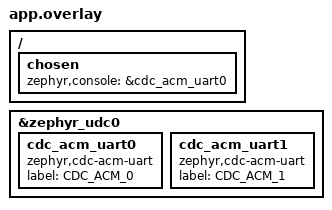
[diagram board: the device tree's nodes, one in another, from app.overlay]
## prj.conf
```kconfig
#
# Copyright (c) Ericsson AB 2020, all rights reserved
#

#General
CONFIG_REBOOT=y
CONFIG_HEAP_MEM_POOL_SIZE=16384
CONFIG_GPIO=y
CONFIG_POLL=y
CONFIG_BOOTLOADER_MCUBOOT=y

 # USB
CONFIG_USB_DEVICE_STACK=y
CONFIG_USB_DEVICE_MANUFACTURER="Ericcson AB"
CONFIG_USB_DEVICE_PRODUCT="Ardesco UART"
CONFIG_USB_DEVICE_VID=0x1915
CONFIG_USB_DEVICE_PID=0x520F
CONFIG_USB_DEVICE_SN="ARDESCO 12PLACEHLDRS"
CONFIG_USB_COMPOSITE_DEVICE=y
CONFIG_USB_CDC_ACM_RINGBUF_SIZE=4096

# Set console to USB output
CONFIG_CONSOLE=y
CONFIG_UART_CONSOLE=y

 # UART
CONFIG_SERIAL=y
CONFIG_UART_INTERRUPT_DRIVEN=y
CONFIG_UART_LINE_CTRL=y

# Need power management for usb_uart
CONFIG_DEVICE_POWER_MANAGEMENT=y
```

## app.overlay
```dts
/*
 * Copyright (c) 2021 Nordic Semiconductor ASA
 *
 * SPDX-License-Identifier: Apache-2.0
 */

/ {
	chosen {
		zephyr,console = &cdc_acm_uart0;
	};
};

&zephyr_udc0 {
	cdc_acm_uart0: cdc_acm_uart0 {
		compatible = "zephyr,cdc-acm-uart";
		label = "CDC_ACM_0";
	};

	cdc_acm_uart1 {
		compatible = "zephyr,cdc-acm-uart";
		label = "CDC_ACM_1";
	};

};
```

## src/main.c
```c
/*
 * Copyright (c) Ericsson AB 2020, all rights reserved
 */

#include <ardesco.h>

#include <usb_uart.h>

void my_debugout_ping(struct k_work *work);

// Timer structure for sending periodic debug strings out USB
struct k_timer my_timer;

// Work structure 
K_WORK_DEFINE(my_work, my_debugout_ping);

//
// my_debugout_ping - Routine to spit out a string on one of 
// the USB uart instances.
//
void my_debugout_ping(struct k_work *work)
{
    printk ("52840 hello\r\n");
}

//
// Timer handler. Spin off real task using g_submit_work
//
void my_timer_handler(struct k_timer *dummy)
{
    k_work_submit(&my_work);
}

//========================================================
// Program Entry Point
//========================================================
void main(void)
{
    printk ("52840 hello\r\n");

	// (db) Start the debug serial out code.
	usb_uart_init();

	// Init timer
	k_timer_init(&my_timer, my_timer_handler, NULL);

	// Start 10 sec timer, 
	k_timer_start(&my_timer, K_SECONDS(2), K_SECONDS(2));

	// Do nothing.
	while (1) 
	{
		//(db)
		k_sleep(K_SECONDS(60));
		k_yield();
                
	}
}
```
